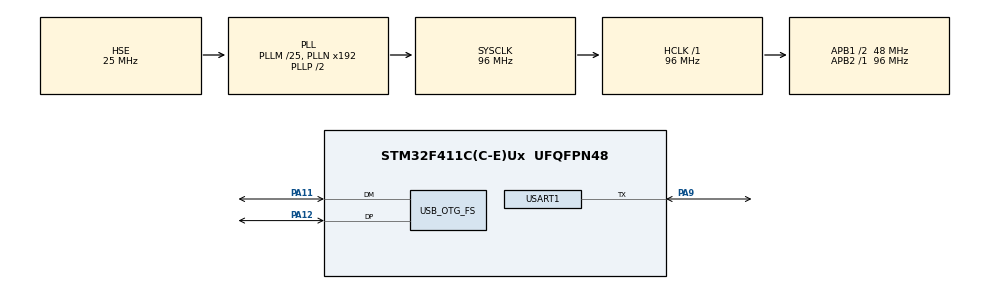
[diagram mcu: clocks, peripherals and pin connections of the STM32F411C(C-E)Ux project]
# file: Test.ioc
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Dma.Request0=USART1_RX
Dma.Request1=USART1_TX
Dma.USART1_RX.0.Direction=DMA_PERIPH_TO_MEMORY
Dma.USART1_RX.0.FIFOMode=DMA_FIFOMODE_DISABLE
Dma.USART1_RX.0.Instance=DMA2_Stream2
Dma.USART1_RX.0.MemDataAlignment=DMA_MDATAALIGN_BYTE
Dma.USART1_RX.0.MemInc=DMA_MINC_ENABLE
Dma.USART1_RX.0.Mode=DMA_CIRCULAR
Dma.USART1_RX.0.PeriphDataAlignment=DMA_PDATAALIGN_BYTE
Dma.USART1_RX.0.PeriphInc=DMA_PINC_DISABLE
Dma.USART1_RX.0.Priority=DMA_PRIORITY_LOW
Dma.USART1_TX.1.Direction=DMA_MEMORY_TO_PERIPH
Dma.USART1_TX.1.FIFOMode=DMA_FIFOMODE_DISABLE
Dma.USART1_TX.1.Instance=DMA2_Stream7
Dma.USART1_TX.1.MemDataAlignment=DMA_MDATAALIGN_BYTE
Dma.USART1_TX.1.MemInc=DMA_MINC_ENABLE
Dma.USART1_TX.1.Mode=DMA_NORMAL
Dma.USART1_TX.1.PeriphDataAlignment=DMA_PDATAALIGN_BYTE
Dma.USART1_TX.1.PeriphInc=DMA_PINC_DISABLE
Dma.USART1_TX.1.Priority=DMA_PRIORITY_LOW
Mcu.Family=STM32F4
Mcu.Name=STM32F411C(C-E)Ux
Mcu.Package=UFQFPN48
NVIC.DMA2_Stream2_IRQn=true\:1\:0\:true\:false\:true\:false\:true\:true
NVIC.DMA2_Stream7_IRQn=true\:1\:0\:true\:false\:true\:false\:true\:true
NVIC.OTG_FS_IRQn=true\:2\:0\:true\:false\:true\:false\:true\:true
NVIC.PriorityGroup=NVIC_PRIORITYGROUP_4
NVIC.USART1_IRQn=true\:1\:0\:true\:false\:true\:true\:true\:true
PA11.Mode=Device_Only
PA11.Signal=USB_OTG_FS_DM
PA12.Mode=Device_Only
PA12.Signal=USB_OTG_FS_DP
PA13.Mode=Serial_Wire
PA13.Signal=SYS_JTMS-SWDIO
PA14.Mode=Serial_Wire
PA14.Signal=SYS_JTCK-SWCLK
PA9.GPIO_PuPd=GPIO_NOPULL
PA9.Mode=Half_duplex(single_wire_mode)
PA9.Signal=USART1_TX
PH0\ -\ OSC_IN.Mode=HSE-External-Oscillator
PH0\ -\ OSC_IN.Signal=RCC_OSC_IN
PH1\ -\ OSC_OUT.Mode=HSE-External-Oscillator
PH1\ -\ OSC_OUT.Signal=RCC_OSC_OUT
ProjectManager.HeapSize=0x200
ProjectManager.StackSize=0x400
ProjectManager.TargetToolchain=STM32CubeIDE
RCC.48MHZClocksFreq_Value=48000000
RCC.AHBFreq_Value=96000000
RCC.APB1CLKDivider=RCC_HCLK_DIV2
RCC.APB1Freq_Value=48000000
RCC.APB1TimFreq_Value=96000000
RCC.APB2Freq_Value=96000000
RCC.APB2TimFreq_Value=96000000
RCC.CortexFreq_Value=96000000
RCC.HCLKFreq_Value=96000000
RCC.HSE_VALUE=25000000
RCC.HSI_VALUE=16000000
RCC.LSE_VALUE=32768
RCC.PLLM=25
RCC.SYSCLKFreq_VALUE=96000000
RCC.SYSCLKSource=RCC_SYSCLKSOURCE_PLLCLK
RCC.VCOOutputFreq_Value=192000000
USART1.BaudRate=1000000
USART1.VirtualMode=VM_ASYNC
USB_DEVICE.CLASS_NAME_FS=CDC
USB_DEVICE.VirtualMode=Cdc
USB_DEVICE.VirtualModeFS=Cdc_FS
USB_OTG_FS.VirtualMode=Device_Only
VP_USB_DEVICE_VS_USB_DEVICE_CDC_FS.Mode=CDC_FS
board=custom

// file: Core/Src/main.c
/* USER CODE BEGIN Header */
/**
  ******************************************************************************
  * @file           : main.c
  * @brief          : Main program body
  ******************************************************************************
  * @attention
  *
  * Copyright (c) 2026 STMicroelectronics.
  * All rights reserved.
  *
  * This software is licensed under terms that can be found in the LICENSE file
  * in the root directory of this software component.
  * If no LICENSE file comes with this software, it is provided AS-IS.
  *
  ******************************************************************************
  */
/* USER CODE END Header */
#include "main.h"
#include "dma.h"
#include "usart.h"
#include "usb_device.h"
#include "gpio.h"

/* USER CODE BEGIN Includes */
#include "usbd_cdc_if.h"
/* USER CODE END Includes */

/* USER CODE BEGIN PV */
#define RX_BUF_SIZE 1024
#define TX_BUF_SIZE 1024

uint8_t uart_rx_buf[RX_BUF_SIZE];
uint8_t uart_tx_buf[TX_BUF_SIZE];
volatile uint8_t tx_active = 0;     // ← ini yang hilang
/* USER CODE END PV */

void SystemClock_Config(void);

int main(void)
{

  /* MCU Configuration--------------------------------------------------------*/

  /* Reset of all peripherals, Initializes the Flash interface and the Systick. */
  HAL_Init();

  /* Configure the system clock */
  SystemClock_Config();

  /* Initialize all configured peripherals */
  MX_GPIO_Init();
  MX_DMA_Init();
  MX_USART1_UART_Init();
  MX_USB_DEVICE_Init();
  /* USER CODE BEGIN 2 */
  HAL_UARTEx_ReceiveToIdle_DMA(&huart1, uart_rx_buf, RX_BUF_SIZE);
  __HAL_DMA_DISABLE_IT(huart1.hdmarx, DMA_IT_HT); // ← tambah ini
  /* USER CODE END 2 */

  /* Infinite loop */
  while (1)
  {

  }
}

void SystemClock_Config(void)
{
  RCC_OscInitTypeDef RCC_OscInitStruct = {0};
  RCC_ClkInitTypeDef RCC_ClkInitStruct = {0};

  /** Configure the main internal regulator output voltage
  */
  __HAL_RCC_PWR_CLK_ENABLE();
  __HAL_PWR_VOLTAGESCALING_CONFIG(PWR_REGULATOR_VOLTAGE_SCALE1);

  /** Initializes the RCC Oscillators according to the specified parameters
  * in the RCC_OscInitTypeDef structure.
  */
  RCC_OscInitStruct.OscillatorType = RCC_OSCILLATORTYPE_HSE;
  RCC_OscInitStruct.HSEState = RCC_HSE_ON;
  RCC_OscInitStruct.PLL.PLLState = RCC_PLL_ON;
  RCC_OscInitStruct.PLL.PLLSource = RCC_PLLSOURCE_HSE;
  RCC_OscInitStruct.PLL.PLLM = 25;
  RCC_OscInitStruct.PLL.PLLN = 192;
  RCC_OscInitStruct.PLL.PLLP = RCC_PLLP_DIV2;
  RCC_OscInitStruct.PLL.PLLQ = 4;
  if (HAL_RCC_OscConfig(&RCC_OscInitStruct) != HAL_OK)
  {
    Error_Handler();
  }

  /** Initializes the CPU, AHB and APB buses clocks
  */
  RCC_ClkInitStruct.ClockType = RCC_CLOCKTYPE_HCLK|RCC_CLOCKTYPE_SYSCLK
                              |RCC_CLOCKTYPE_PCLK1|RCC_CLOCKTYPE_PCLK2;
  RCC_ClkInitStruct.SYSCLKSource = RCC_SYSCLKSOURCE_PLLCLK;
  RCC_ClkInitStruct.AHBCLKDivider = RCC_SYSCLK_DIV1;
  RCC_ClkInitStruct.APB1CLKDivider = RCC_HCLK_DIV2;
  RCC_ClkInitStruct.APB2CLKDivider = RCC_HCLK_DIV1;

  if (HAL_RCC_ClockConfig(&RCC_ClkInitStruct, FLASH_LATENCY_3) != HAL_OK)
  {
    Error_Handler();
  }
}

/* USER CODE BEGIN 4 */
// FIX BUG #2: Dipicu saat pengiriman paket dari PC ke Servo selesai sepenuhnya
// Dipicu saat pengiriman paket dari PC ke Servo selesai sepenuhnya
void HAL_UART_TxCpltCallback(UART_HandleTypeDef *huart)
{
    if (huart->Instance == USART1)
    {
        tx_active = 0;
        HAL_GPIO_TogglePin(GPIOC, GPIO_PIN_13); // heartbeat debug, boleh dihapus nanti

        HAL_UARTEx_ReceiveToIdle_DMA(&huart1, uart_rx_buf, RX_BUF_SIZE);
        __HAL_DMA_DISABLE_IT(huart1.hdmarx, DMA_IT_HT);
    }
}

// Dipicu otomatis saat Servo selesai mengirim paket balik (Idle Line Detected)
void HAL_UARTEx_RxEventCallback(UART_HandleTypeDef *huart, uint16_t Size)
{
    if (huart->Instance == USART1)
    {
        if (Size > 0 && Size <= RX_BUF_SIZE)
        {
            CDC_Transmit_FS(uart_rx_buf, Size); // non-blocking, abaikan return
        }

        HAL_UARTEx_ReceiveToIdle_DMA(&huart1, uart_rx_buf, RX_BUF_SIZE);
        __HAL_DMA_DISABLE_IT(huart1.hdmarx, DMA_IT_HT);
    }
}

void HAL_UART_ErrorCallback(UART_HandleTypeDef *huart)
{
    if (huart->Instance == USART1)
    {
        volatile uint32_t tmp;
        tmp = huart->Instance->SR;
        tmp = huart->Instance->DR;
        (void)tmp;

        tx_active = 0;

        HAL_UARTEx_ReceiveToIdle_DMA(&huart1, uart_rx_buf, RX_BUF_SIZE);
        __HAL_DMA_DISABLE_IT(huart1.hdmarx, DMA_IT_HT);
    }
}
/* USER CODE END 4 */

void Error_Handler(void)
{
  __disable_irq();
  while (1)
  {
  }
}
